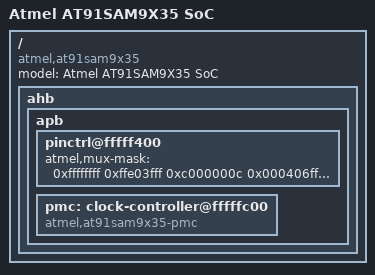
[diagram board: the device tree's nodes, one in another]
#include "at91sam9x5.dtsi"
#include "at91sam9x5_lcd.dtsi"
#include "at91sam9x5_macb0.dtsi"
#include "at91sam9x5_can.dtsi"
/ {
	model = "Atmel AT91SAM9X35 SoC";
	compatible = "atmel,at91sam9x35", "atmel,at91sam9x5";
	ahb {
		apb {
			pinctrl@fffff400 {
				atmel,mux-mask = <
				       0xffffffff 0xffe03fff 0xc000000c   
				       0x000406ff 0x00047e3f 0x00000000   
				       0xfdffffff 0x00000000 0xb83fffff   
				       0x003fffff 0x003f8000 0x00000000   
				      >;
			};
			pmc: clock-controller@fffffc00 {
				compatible = "atmel,at91sam9x35-pmc", "atmel,at91sam9x5-pmc", "syscon";
			};
		};
	};
};
